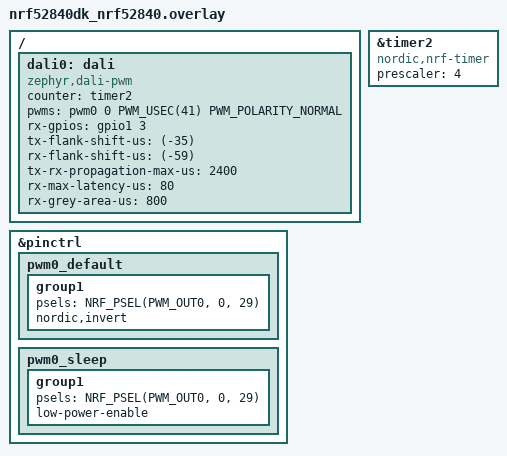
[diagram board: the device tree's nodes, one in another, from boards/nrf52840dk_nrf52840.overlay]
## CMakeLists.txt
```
cmake_minimum_required(VERSION 3.20.0)
find_package(Zephyr REQUIRED HINTS $ENV{ZEPHYR_BASE})
project(dali_app LANGUAGES C)

include(${ZEPHYR_BASE}/samples/subsys/usb/common/common.cmake)
target_sources(app PRIVATE src/main.c)
```

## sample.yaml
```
sample:
  description: DALI Logger application
  name: dali-logger
common:
  build_only: true
  integration_platforms:
    - nrf52840dk/nrf52840
tests:
  app.default: {}
  app.debug:
    extra_overlay_confs:
      - debug.conf
```

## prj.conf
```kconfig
CONFIG_DALI=y

CONFIG_LOG=y
CONFIG_LOG_BACKEND_SHOW_COLOR=n
CONFIG_LOG_BACKEND_SHOW_LEVEL=n
CONFIG_LOG_FUNC_NAME_PREFIX_DBG=n
CONFIG_LOG_BACKEND_SHOW_TIMESTAMP=y
CONFIG_LOG_BACKEND_FORMAT_TIMESTAMP=n

CONFIG_DALI_LOW_LEVEL_LOG_LEVEL_OFF=y
```

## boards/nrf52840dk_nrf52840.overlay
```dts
/*
 * Copyright 2025 by Markus Becker
 * SPDX-License-Identifier: Apache-2.0
 *
 * add DALI 2 Click (MIKROE-2672)
 * via Arduino UNO click shield (MIKROE-1581)
 * to nRF52840 DK (pca10056)
 * DALI 2 Click
 *   DALI TX 2
 *   DALI RX 15
 * Arduino UNO click shield:
 *   DALI TX 2  > A3
 *   DALI RX 15 > D2
 * nRF52840 DK:
 *   DALI TX A3 > P0.29
 *   DALI RX D2 > P1.03
 */

/ {
	dali0: dali {
		compatible = "zephyr,dali-pwm";
		status = "okay";
		counter = <&timer2>;
		pwms = <&pwm0 0 PWM_USEC(41) PWM_POLARITY_NORMAL>;
		rx-gpios = <&gpio1 3 GPIO_ACTIVE_HIGH>; // D2
		tx-flank-shift-us = <(-35)>;
		rx-flank-shift-us = <(-59)>;
		tx-rx-propagation-max-us = <2400>;
		rx-max-latency-us = <80>;
		rx-grey-area-us = <800>;
	};
};

&pinctrl {
	pwm0_default: pwm0_default {
		group1 {
			psels = <NRF_PSEL(PWM_OUT0, 0, 29)>; // A3
			nordic,invert;
		};
	};

	pwm0_sleep: pwm0_sleep {
		group1 {
			psels = <NRF_PSEL(PWM_OUT0, 0, 29)>; // A3
			low-power-enable;
		};
	};
};

&timer2 {
	compatible = "nordic,nrf-timer";
	status = "okay";
	prescaler = <4>;
};
```

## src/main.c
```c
/*
 * Copyright (c) 2025 by Markus Becker <markushx@gmail.com>
 * SPDX-License-Identifier: Apache-2.0
 */

#include <zephyr/kernel.h>
#include <zephyr/device.h>
#include <zephyr/drivers/dali.h>

#include <zephyr/logging/log.h>
LOG_MODULE_REGISTER(D, LOG_LEVEL_INF);

static uint32_t packet_counter;

void dali_rx_callback(const struct device *dev, struct dali_frame frame, void *user_data)
{
	LOG_INF("RX %u %u %x", packet_counter++, frame.event_type, frame.data);
}

#define DALI_NODE DT_NODELABEL(dali0)

int main(void)
{
	LOG_INF("DALI Logger");
	LOG_INF("Target board: %s", CONFIG_BOARD_TARGET);

	/* get the DALI device */
	const struct device *dali_dev = DEVICE_DT_GET(DALI_NODE);

	if (!device_is_ready(dali_dev)) {
		LOG_ERR("failed to get DALI device.");
		return 0;
	}

	dali_receive(dali_dev, dali_rx_callback, NULL);

	/* idle and wait for callbacks */
	for (;;) {
		k_sleep(K_MSEC(60000));
		LOG_INF("ALIVE");
	}
	return 0;
}
```
